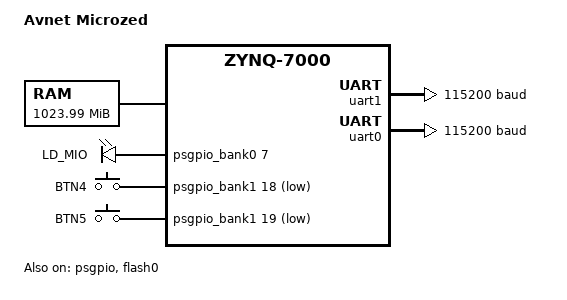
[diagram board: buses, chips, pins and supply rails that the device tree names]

/dts-v1/;
#include <xilinx/zynq7000.dtsi>
#include <zephyr/dt-bindings/gpio/gpio.h>
#include <zephyr/dt-bindings/input/input-event-codes.h>

#include "microzed-pinctrl.dtsi"

/ {
	model = "Avnet Microzed";
	compatible = "avnet,zynq-microzed", "xlnx,zynq-7000";

	#address-cells = <1>;
	#size-cells = <1>;

	chosen {
        	zephyr,sram = &ddr0;
        	zephyr,flash = &flash0;
		zephyr,console = &uart1;
		zephyr,shell-uart = &uart1;
		zephyr,ocm = &ocm_high;
	};

	aliases {
		led0 = &ld_mio;
		sw0 = &btn4;
		sw1 = &btn5;
		console = &uart1;
	};

	cpus {
		#address-cells = <1>;
		#size-cells = <0>;

		cpu0: cpu@0 {
			device_type = "cpu";
			compatible = "arm,cortex-a9";
			reg = <0>;
		};

		cpu1: cpu@1 {
			device_type = "cpu";
			compatible = "arm,cortex-a9";
			reg = <1>;
		};
	};

    /* ~1 GiB DDR for .data/.bss */
    ddr0: memory@3000 {
        device_type             = "memory";
        reg                     = <0x3000 0x3FFFD000>;
        label                  = "ddr0";
    };

    flash0: flash@e0002000 {
        compatible = "xlnx,zynq-qspi-1.0";
        reg = <0xe000D000 0x1000>;
        interrupts = <0 19 4 0>;
        interrupt-parent = <&gic>;
        status = "okay";
        partitions {
            compatible = "fixed-partitions";
            #address-cells = <1>;
            #size-cells = <1>;
            boot_partition: partition@0 {
                label = "boot";
                reg = <0x00000000 0x00040000>;
                read-only;
            };
            storage_partition: partition@40000 {
                label = "storage";
                reg = <0x00040000 0x000C0000>;
            };
        };
    };

	leds {
		compatible = "gpio-leds";
		ld_mio: led_mio {
			gpios = <&psgpio_bank0 7 GPIO_ACTIVE_HIGH>;
			label = "LD_MIO";
		};
	};

	gpio_keys {
		compatible = "gpio-keys";
		btn4: btn4 {
			gpios = <&psgpio_bank1 18 GPIO_ACTIVE_LOW>;
			label = "BTN4";
			zephyr,code = <INPUT_KEY_0>;
		};
		btn5: btn5 {
			gpios = <&psgpio_bank1 19 GPIO_ACTIVE_LOW>;
			label = "BTN5";
			zephyr,code = <INPUT_KEY_1>;
		};
	};
};

&uart1 {
	status = "okay";
	current-speed = <115200>;
	clock-frequency = <50000000>;
	pinctrl-0 = <&pinctrl_uart1_default>;
	pinctrl-names = "default";
};

&uart0 {
	status = "okay";
	current-speed = <115200>;
	clock-frequency = <50000000>;
};

&psgpio {
	status = "okay";
};

&gic {
    #address-cells = <0>;
};

